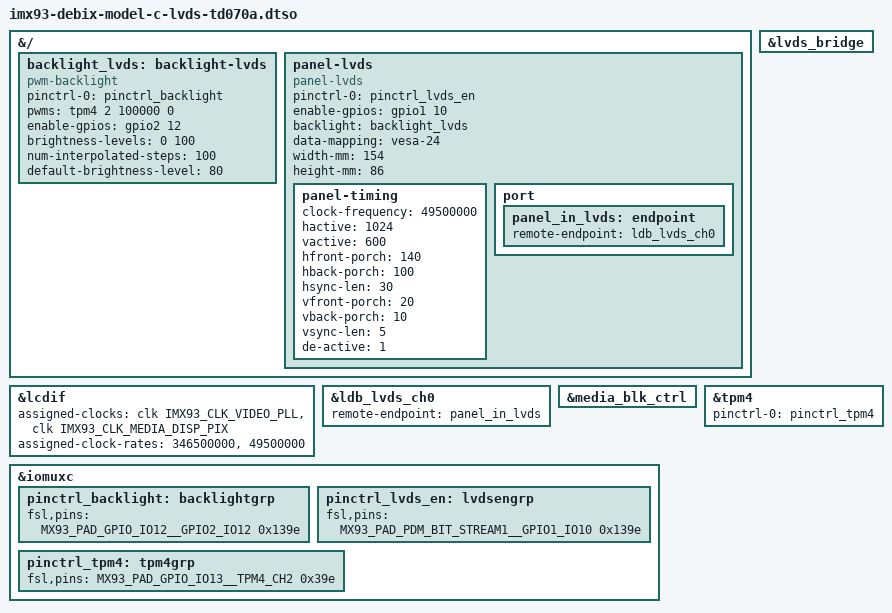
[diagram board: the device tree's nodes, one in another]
// SPDX-License-Identifier: (GPL-2.0+ OR MIT)
/*
 * DEBIX TD070A 7" LVDS panel (JW070R0520B02, 1024x600) on DEBIX Model C.
 * Timing from the vendor panel-simple driver. Pins from the vendor DTS.
 */

/dts-v1/;
/plugin/;

#include <dt-bindings/clock/imx93-clock.h>
#include <dt-bindings/gpio/gpio.h>
#include "../imx93-pinfunc.h"

&{/} {
	backlight_lvds: backlight-lvds {
		compatible = "pwm-backlight";
		pinctrl-names = "default";
		pinctrl-0 = <&pinctrl_backlight>;
		pwms = <&tpm4 2 100000 0>;
		enable-gpios = <&gpio2 12 GPIO_ACTIVE_HIGH>;
		brightness-levels = <0 100>;
		num-interpolated-steps = <100>;
		default-brightness-level = <80>;
	};

	panel-lvds {
		compatible = "panel-lvds";
		pinctrl-names = "default";
		pinctrl-0 = <&pinctrl_lvds_en>;
		enable-gpios = <&gpio1 10 GPIO_ACTIVE_HIGH>;
		backlight = <&backlight_lvds>;
		data-mapping = "vesa-24";
		width-mm = <154>;
		height-mm = <86>;

		panel-timing {
			clock-frequency = <49500000>;
			hactive = <1024>;
			vactive = <600>;
			hfront-porch = <140>;
			hback-porch = <100>;
			hsync-len = <30>;
			vfront-porch = <20>;
			vback-porch = <10>;
			vsync-len = <5>;
			de-active = <1>;
		};

		port {
			panel_in_lvds: endpoint {
				remote-endpoint = <&ldb_lvds_ch0>;
			};
		};
	};
};

/* LVDS serial clock is 7x the pixel clock */
&lcdif {
	assigned-clocks = <&clk IMX93_CLK_VIDEO_PLL>,
			  <&clk IMX93_CLK_MEDIA_DISP_PIX>;
	assigned-clock-rates = <346500000>, <49500000>;
	status = "okay";
};

&ldb_lvds_ch0 {
	remote-endpoint = <&panel_in_lvds>;
};

&lvds_bridge {
	status = "okay";
};

&media_blk_ctrl {
	status = "okay";
};

&tpm4 {
	pinctrl-names = "default";
	pinctrl-0 = <&pinctrl_tpm4>;
	status = "okay";
};

&iomuxc {
	pinctrl_backlight: backlightgrp {
		fsl,pins = <
			MX93_PAD_GPIO_IO12__GPIO2_IO12			0x139e
		>;
	};

	pinctrl_lvds_en: lvdsengrp {
		fsl,pins = <
			MX93_PAD_PDM_BIT_STREAM1__GPIO1_IO10		0x139e
		>;
	};

	pinctrl_tpm4: tpm4grp {
		fsl,pins = <
			MX93_PAD_GPIO_IO13__TPM4_CH2			0x39e
		>;
	};
};
